# SWM201 register map
File version: 1.0
SWM201 Microcontroller registers
CPU: CM0 r1p0, little endian, 2 interrupt priority bits
Registers are 32-bit, read-write, no defined reset value unless marked. A register's access mark holds for its fields unless they carry their own. Offsets are from the block's base; lines under a group give offsets from that group; [hi:lo] are bit positions; {n}, {i} and the like mark numbered series; 'fields as' and 'values as' point back to an identical list; <NAME> marks a mode.

## Memory map
0x40000000 SYS size 0xAA08C — Registers group
0x40003000 CORDIC size 0x20 — Registers group
0x40003800 DIV size 0x28 — Registers group
0x40004000 GPIOM size 0x80
0x40040000 GPIOA size 0x80 — Registers group
0x40040800 GPIOB size 0x80
0x40042000 UART0 size 0x20 — Registers group
0x40042800 UART1 size 0x20
0x40044000 SPI0 size 0x28 — Registers group
0x40046000 PWM0 size 0x80 — Registers group
0x40046080 PWM1 size 0x80
0x40046400 PWMG size 0x28 — Registers group
0x40046800 TIMR0 size 0x34 — Registers group
0x40046840 TIMR1 size 0x34
0x40046C00 TIMRG size 0x44 — Registers group
0x40048800 BTIMR0 size 0x34
0x40048840 BTIMR1 size 0x34
0x40048880 BTIMR2 size 0x34
0x400488C0 BTIMR3 size 0x34
0x40048C00 BTIMRG size 0x44
0x40049000 ADC0 size 0x1FC — Registers group
0x4004A000 FMC size 0x24 — Registers group
0x4004B800 RTC size 0x34 — Registers group
0x4004D800 QEI size 0x34 — Registers group
0x400A0000 PORTA size 0x404 — Registers group
0x400A0010 PORTB size 0x404
0x400A0080 PORTM size 0x404
0x400A0800 WDT size 0x14 — Registers group
0x400A6000 I2C0 size 0x38 — Registers group

## SYS — Registers group
Base 0x40000000
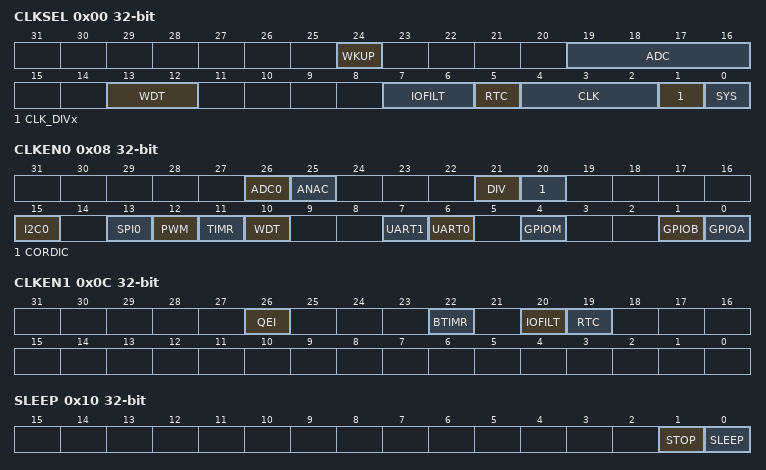
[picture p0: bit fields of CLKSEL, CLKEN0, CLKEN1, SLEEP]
0x00 CLKSEL
  [24] WKUP, [19:16] ADC, [13:12] WDT, [7:6] IOFILT, [5] RTC, [4:2] CLK, [1] CLK_DIVx, [0] SYS
0x04 CLKDIVx_ON
0x08 CLKEN0
  [26] ADC0, [25] ANAC, [21] DIV, [20] CORDIC, [15] I2C0, [13] SPI0, [12] PWM, [11] TIMR, [10] WDT, [7] UART1, [6] UART0, [4] GPIOM, [1] GPIOB, [0] GPIOA
0x0C CLKEN1
  [26] QEI, [22] BTIMR, [20] IOFILT, [19] RTC
0x10 SLEEP
  [1] STOP, [0] SLEEP
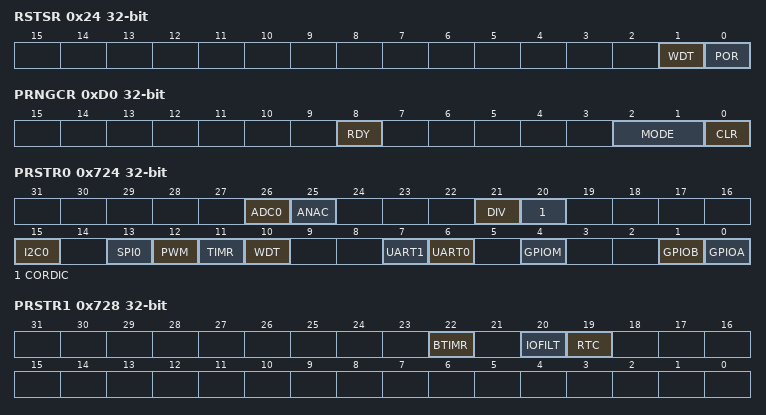
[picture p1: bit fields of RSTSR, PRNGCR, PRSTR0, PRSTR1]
0x24 RSTSR
  [1] WDT, [0] POR
0x30 RTCWKCR
  [0] EN
0x34 RTCWKSR
  [0] FLAG
{0x80+4i} CHIPID[{i}] (i=0..3) ro
{0x90+4i} BACKUP[{i}] (i=0..3)
0xD0 PRNGCR
  [8] RDY, [2:1] MODE, [0] CLR
0xD4 PRNGDL
0xD8 PRNGDH
0x100 PAWKEN
0x104 PBWKEN
0x120 PMWKEN
0x130 PAWKSR
0x134 PBWKSR
0x150 PMWKSR
0x400 IOFILT0
0x404 IOFILT1
0x720 PRSTEN
0x724 PRSTR0
  fields as CLKEN0
0x728 PRSTR1
  [22] BTIMR, [20] IOFILT, [19] RTC
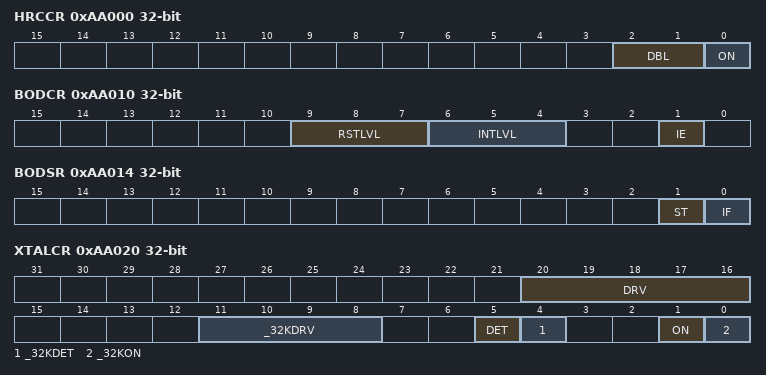
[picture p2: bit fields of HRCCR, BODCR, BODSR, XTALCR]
0xAA000 HRCCR
  [2:1] DBL, [0] ON
0xAA010 BODCR
  [9:7] RSTLVL, [6:4] INTLVL, [1] IE
0xAA014 BODSR
  [1] ST, [0] IF
0xAA020 XTALCR
  [20:16] DRV, [11:8] _32KDRV, [5] DET, [4] _32KDET, [1] ON, [0] _32KON
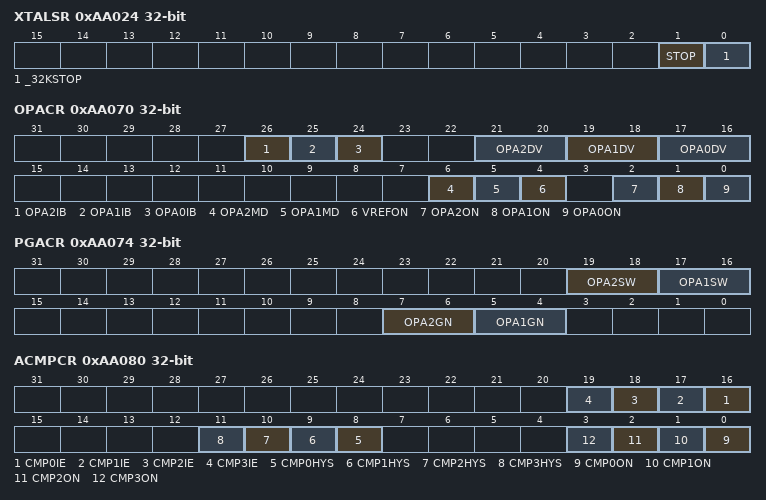
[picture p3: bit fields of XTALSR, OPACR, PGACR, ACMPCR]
0xAA024 XTALSR
  [1] STOP, [0] _32KSTOP
0xAA050 LRCCR
  [0] ON
0xAA070 OPACR
  [26] OPA2IB, [25] OPA1IB, [24] OPA0IB, [21:20] OPA2DV, [19:18] OPA1DV, [17:16] OPA0DV, [6] OPA2MD, [5] OPA1MD, [4] VREFON, [2] OPA2ON, [1] OPA1ON, [0] OPA0ON
0xAA074 PGACR
  [19:18] OPA2SW, [17:16] OPA1SW, [7:6] OPA2GN, [5:4] OPA1GN
0xAA080 ACMPCR
  [n+16] CMP{n}IE (n=0..3), [n+8] CMP{n}HYS (n=0..3), [n] CMP{n}ON (n=0..3)
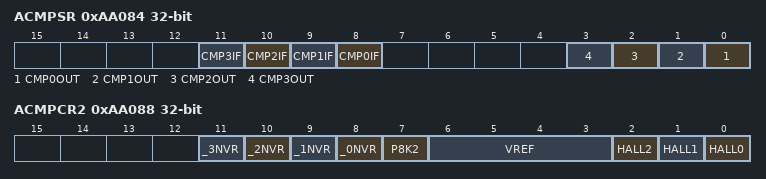
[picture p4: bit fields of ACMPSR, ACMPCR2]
0xAA084 ACMPSR
  [n+8] CMP{n}IF (n=0..3), [n] CMP{n}OUT (n=0..3)
0xAA088 ACMPCR2
  [n+8] _{n}NVR (n=0..3), [7] P8K2, [6:3] VREF, [2] HALL2, [1] HALL1, [0] HALL0

## PORTA — Registers group
Base 0x400A0000
Same registers: PORTB 0x400A0010, PORTM 0x400A0080
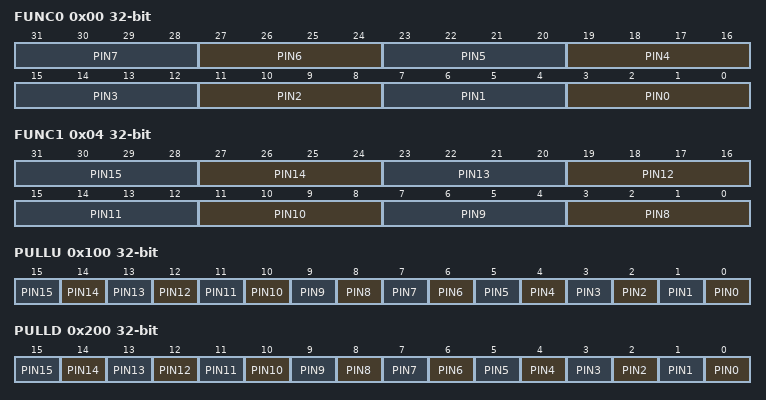
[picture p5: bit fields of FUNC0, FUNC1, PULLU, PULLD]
0x00 FUNC0
  [4n+3:4n] PIN{n} (n=0..7)
0x04 FUNC1
  [4n-29:4n-32] PIN{n} (n=8..15)
0x100 PULLU
  [n] PIN{n} (n=0..15)
0x200 PULLD
  [n] PIN{n} (n=0..15)
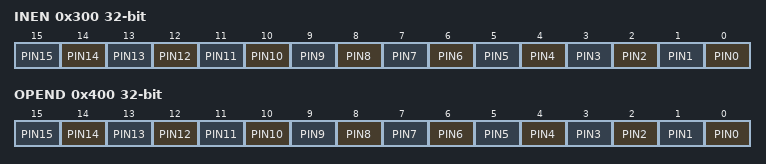
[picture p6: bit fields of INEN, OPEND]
0x300 INEN
  [n] PIN{n} (n=0..15)
0x400 OPEND
  [n] PIN{n} (n=0..15)

## GPIOA — Registers group
Base 0x40040000
Same registers: GPIOM 0x40004000, GPIOB 0x40040800
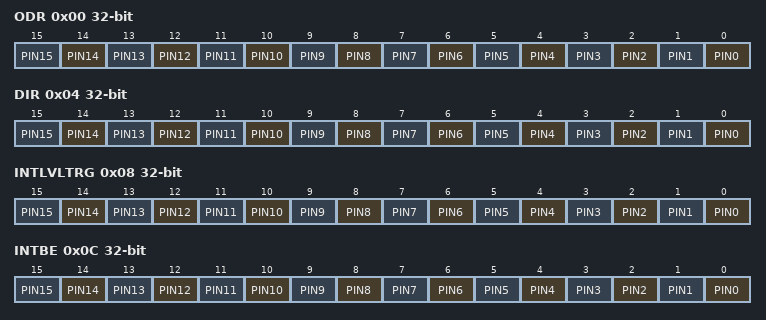
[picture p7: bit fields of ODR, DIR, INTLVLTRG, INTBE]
0x00 ODR
  [n] PIN{n} (n=0..15)
0x04 DIR
  [n] PIN{n} (n=0..15)
0x08 INTLVLTRG
  [n] PIN{n} (n=0..15)
0x0C INTBE
  [n] PIN{n} (n=0..15)
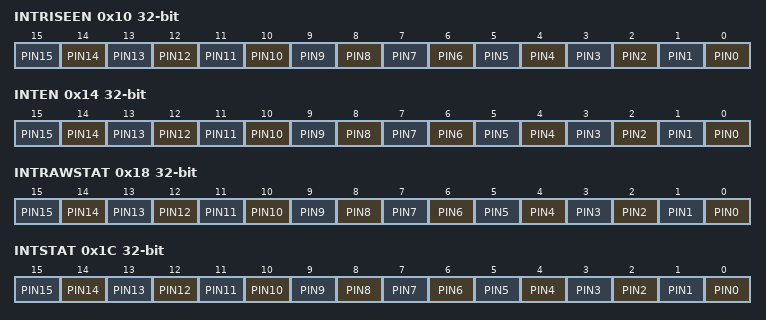
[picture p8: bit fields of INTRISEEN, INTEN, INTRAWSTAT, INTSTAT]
0x10 INTRISEEN
  [n] PIN{n} (n=0..15)
0x14 INTEN
  [n] PIN{n} (n=0..15)
0x18 INTRAWSTAT
  [n] PIN{n} (n=0..15)
0x1C INTSTAT
  [n] PIN{n} (n=0..15)
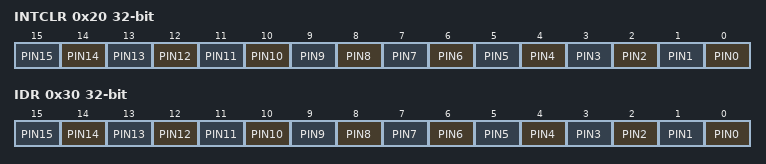
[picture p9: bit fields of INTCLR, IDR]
0x20 INTCLR
  [n] PIN{n} (n=0..15)
0x30 IDR
  [n] PIN{n} (n=0..15)
{0x40+4i} DATAPIN{i} (i=0..15)
